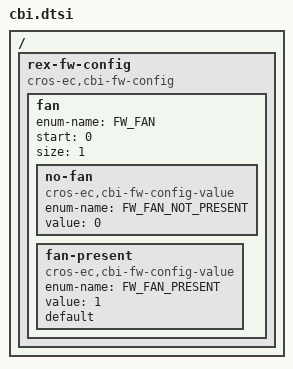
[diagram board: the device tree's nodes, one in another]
/* Copyright 2022 The ChromiumOS Authors
 * Use of this source code is governed by a BSD-style license that can be
 * found in the LICENSE file.
 */

/ {
	rex-fw-config {
		compatible = "cros-ec,cbi-fw-config";

		/*
		 * FW_CONFIG field to enable fan or not.
		 */
		fan {
			enum-name = "FW_FAN";
			start = <0>;
			size = <1>;

			no-fan {
				compatible = "cros-ec,cbi-fw-config-value";
				enum-name = "FW_FAN_NOT_PRESENT";
				value = <0>;
			};
			fan-present {
				compatible = "cros-ec,cbi-fw-config-value";
				enum-name = "FW_FAN_PRESENT";
				value = <1>;
				/*
				 * Set as default so that unprovisioned
				 * configs will run the fan regardless.
				 */
				default;
			};
		};
	};
};
